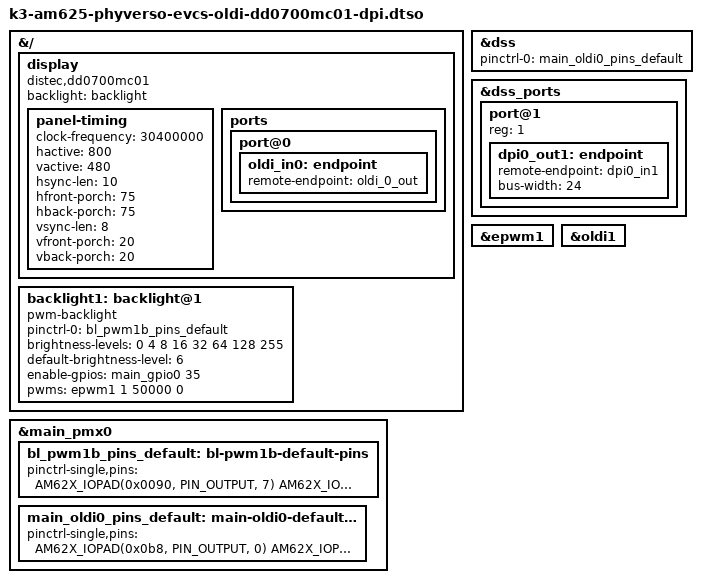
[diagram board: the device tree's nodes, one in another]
// SPDX-License-Identifier: GPL-2.0-only OR MIT
/*
 * Copyright (C) 2026 PHYTEC Messtechnik GmbH
 * Author: Alexander Bauer <a.bauer@phytec.de>
 */

/dts-v1/;
/plugin/;

#include <dt-bindings/pwm/pwm.h>
#include <dt-bindings/gpio/gpio.h>
#include <dt-bindings/interrupt-controller/irq.h>
#include "k3-pinctrl.h"

&{/} {
	display: display {
		compatible = "distec,dd0700mc01", "panel-dpi";
		backlight = <&backlight>;

		panel-timing {
			/* 800x480 */
			clock-frequency = <30400000>;
			hactive = <800>;
			vactive = <480>;
			hsync-len = <10>;
			hfront-porch = <75>;
			hback-porch = <75>;
			vsync-len = <8>;
			vfront-porch = <20>;
			vback-porch = <20>;
		};

		ports {
			#address-cells = <1>;
			#size-cells = <0>;

			port@0 {
				oldi_in0: endpoint {
					remote-endpoint = <&oldi_0_out>;
				};
			};
		};
	};

	backlight1: backlight@1 {
		pinctrl-names = "default";
		pinctrl-0 = <&bl_pwm1b_pins_default>;

		compatible = "pwm-backlight";

		brightness-levels = <0 4 8 16 32 64 128 255>;
		default-brightness-level = <6>;

		enable-gpios = <&main_gpio0 35 GPIO_ACTIVE_HIGH>;
		pwms = <&epwm1 1 50000 0>;
	};
};

&dss {
	pinctrl-names = "default";
	pinctrl-0 = <&main_oldi0_pins_default>;
	status = "okay";
};

&dss_ports {
	#address-cells = <1>;
	#size-cells = <0>;

	/* VP2: DPI Output */
	port@1 {
		reg = <1>;

		dpi0_out1: endpoint {
			remote-endpoint = <&dpi0_in1>;
			bus-width = <24>;
		};
	};
};

&epwm1 {
	status = "okay";
};

&main_pmx0 {
	pinctrl-names = "default";

	bl_pwm1b_pins_default: bl-pwm1b-default-pins {
		pinctrl-single,pins = <
			AM62X_IOPAD(0x0090, PIN_OUTPUT, 7) /* (M24) GPMC0_BE0n_CLE.GPIO0_35 */
			AM62X_IOPAD(0x01a0, PIN_OUTPUT, 6) /* (E18) MCASP0_AXR0.EHRPWM1_B */
		>;
	};

	main_oldi0_pins_default: main-oldi0-default-pins {
		pinctrl-single,pins = <
			AM62X_IOPAD(0x0b8, PIN_OUTPUT, 0) /* (U22) VOUT0_DATA0 */
			AM62X_IOPAD(0x0bc, PIN_OUTPUT, 0) /* (V24) VOUT0_DATA1 */
			AM62X_IOPAD(0x0e0, PIN_OUTPUT, 0) /* (V20) VOUT0_DATA10 */
			AM62X_IOPAD(0x0e4, PIN_OUTPUT, 0) /* (AA23) VOUT0_DATA11 */
			AM62X_IOPAD(0x0e8, PIN_OUTPUT, 0) /* (AB25) VOUT0_DATA12 */
			AM62X_IOPAD(0x0ec, PIN_OUTPUT, 0) /* (AA24) VOUT0_DATA13 */
			AM62X_IOPAD(0x0f0, PIN_OUTPUT, 0) /* (Y22) VOUT0_DATA14 */
			AM62X_IOPAD(0x0f4, PIN_OUTPUT, 0) /* (AA21) VOUT0_DATA15 */
			AM62X_IOPAD(0x005c, PIN_OUTPUT, 1) /* (R24) GPMC0_AD8.VOUT0_DATA16 */
			AM62X_IOPAD(0x0060, PIN_OUTPUT, 1) /* (R25) GPMC0_AD9.VOUT0_DATA17 */
			AM62X_IOPAD(0x0064, PIN_OUTPUT, 1) /* (T25) GPMC0_AD10.VOUT0_DATA18 */
			AM62X_IOPAD(0x0068, PIN_OUTPUT, 1) /* (R21) GPMC0_AD11.VOUT0_DATA19 */
			AM62X_IOPAD(0x006c, PIN_OUTPUT, 1) /* (T22) GPMC0_AD12.VOUT0_DATA20 */
			AM62X_IOPAD(0x0070, PIN_OUTPUT, 1) /* (T24) GPMC0_AD13.VOUT0_DATA21 */
			AM62X_IOPAD(0x0074, PIN_OUTPUT, 1) /* (U25) GPMC0_AD14.VOUT0_DATA22 */
			AM62X_IOPAD(0x0078, PIN_OUTPUT, 1) /* (U24) GPMC0_AD15.VOUT0_DATA23 */

			AM62X_IOPAD(0x0c0, PIN_OUTPUT, 0) /* (W25) VOUT0_DATA2 */
			AM62X_IOPAD(0x0c4, PIN_OUTPUT, 0) /* (W24) VOUT0_DATA3 */
			AM62X_IOPAD(0x0c8, PIN_OUTPUT, 0) /* (Y25) VOUT0_DATA4 */
			AM62X_IOPAD(0x0cc, PIN_OUTPUT, 0) /* (Y24) VOUT0_DATA5 */
			AM62X_IOPAD(0x0d0, PIN_OUTPUT, 0) /* (Y23) VOUT0_DATA6 */
			AM62X_IOPAD(0x0d4, PIN_OUTPUT, 0) /* (AA25) VOUT0_DATA7 */
			AM62X_IOPAD(0x0d8, PIN_OUTPUT, 0) /* (V21) VOUT0_DATA8 */
			AM62X_IOPAD(0x0dc, PIN_OUTPUT, 0) /* (W21) VOUT0_DATA9 */
			AM62X_IOPAD(0x0fc, PIN_OUTPUT, 0) /* (Y20) VOUT0_DE */
			AM62X_IOPAD(0x0f8, PIN_OUTPUT, 0) /* (AB24) VOUT0_HSYNC */
			AM62X_IOPAD(0x104, PIN_OUTPUT, 0) /* (AC24) VOUT0_PCLK */
			AM62X_IOPAD(0x100, PIN_OUTPUT, 0) /* (AC25) VOUT0_VSYNC */
		>;
	};
};

&oldi1 {
	status = "okay";
};
